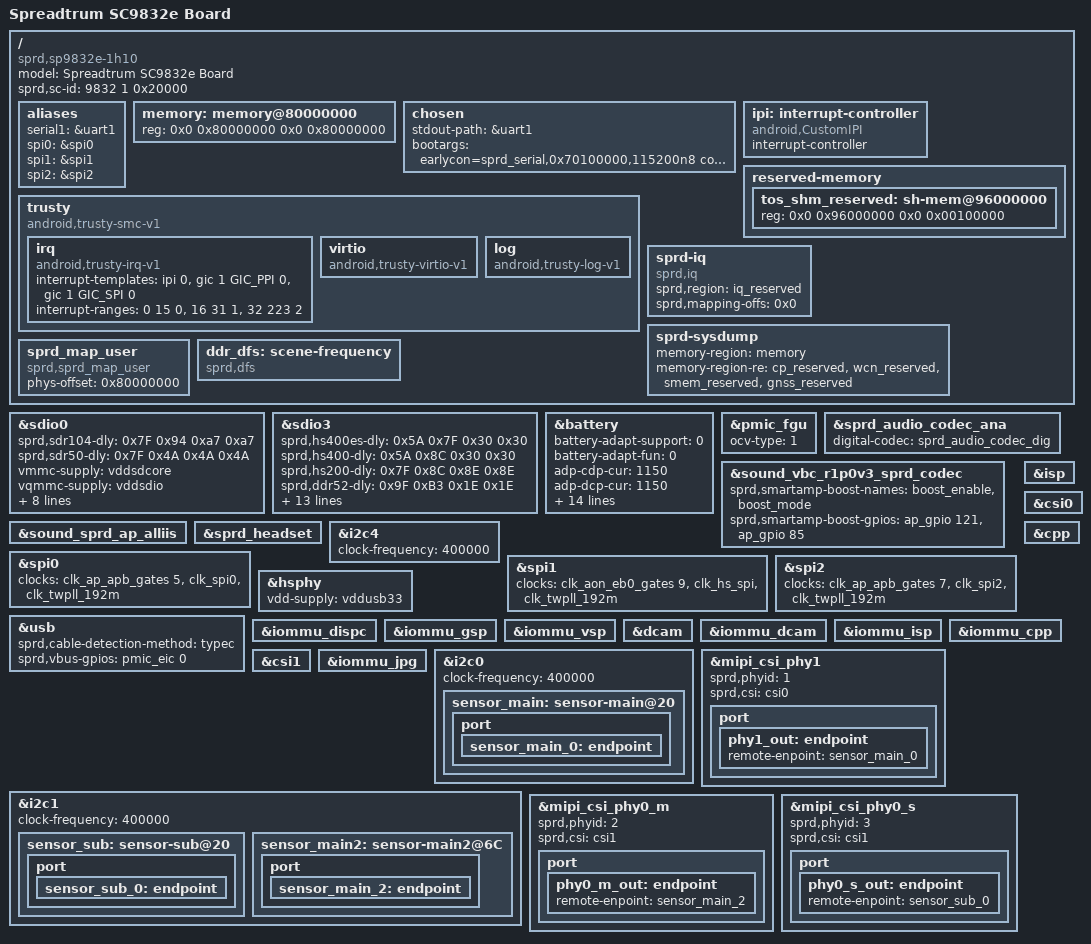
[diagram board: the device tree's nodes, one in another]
/*
 * Spreadtrum sharkle sp9832e board DTS file
 *
 * Copyright (C) 2017, Spreadtrum Communications Inc.
 *
 * This file is licensed under a dual GPLv2 or X11 license.
 */
/dts-v1/;

#include "sp9832e-common.dtsi"

/ {
	model = "Spreadtrum SC9832e Board";

	compatible = "sprd,sp9832e-1h10", "sprd,sc9832e";

	sprd,sc-id = <9832 1 0x20000>;

	aliases {
		serial1 = &uart1;
		spi0 = &spi0;
		spi1 = &spi1;
		spi2 = &spi2;
	};

	memory: memory@80000000 {
		device_type = "memory";
		reg = <0x0 0x80000000 0x0 0x80000000>;
	};

	chosen {
		stdout-path = &uart1;
		bootargs = "earlycon=sprd_serial,0x70100000,115200n8 console=ttyS1,115200n8 loglevel=1 init=/init root=/dev/mmcblk0p30 rootfstype=ext4 ro rootwait androidboot.hardware=sp9832e_1h10 androidboot.dtbo_idx=0";
	};

	ipi: interrupt-controller {
		compatible = "android,CustomIPI";
		#interrupt-cells = <1>;
		interrupt-controller;
	};

	/* reserved memory for spec board */
	reserved-memory {
		#address-cells = <2>;
		#size-cells = <2>;
		ranges;

		tos_shm_reserved: sh-mem@96000000{
			reg = <0x0 0x96000000 0x0 0x00100000>;
		};
	};

	trusty {
		compatible = "android,trusty-smc-v1";

		irq {
			compatible = "android,trusty-irq-v1";
			interrupt-templates = <&ipi 0>,
						<&gic 1 GIC_PPI 0>,
						<&gic 1 GIC_SPI 0>;
			interrupt-ranges = < 0  15 0>,
						<16  31 1>,
						<32 223 2>;
		};

		virtio {
			compatible = "android,trusty-virtio-v1";
		};

		log {
			compatible = "android,trusty-log-v1";
		};
	};

	sprd-iq {
		compatible = "sprd,iq";
		sprd,region = <&iq_reserved>;
		sprd,mapping-offs = <0x0>;
	};

	sprd-sysdump {
		memory-region = <&memory>;
		memory-region-re = <&cp_reserved>, <&wcn_reserved>,
				   <&smem_reserved>, <&gnss_reserved>;
	};

	sprd_map_user {
		compatible = "sprd,sprd_map_user";
		phys-offset = <0x80000000>;
	};

	ddr_dfs: scene-frequency {
		compatible = "sprd,dfs";
	};
};

&sdio0 {
	sprd,sdr104-dly = <0x7F 0x94 0xa7 0xa7>;
	sprd,sdr50-dly = <0x7F 0x4A 0x4A 0x4A>;
	vmmc-supply = <&vddsdcore>;
	vqmmc-supply = <&vddsdio>;
	voltage-ranges = <3000 3000>;
	bus-width = <4>;
	cd-gpios = <&ap_gpio 78 1>;
	sd-uhs-sdr50;
	sprd,name = "sdio_sd";
	sprd,sdio-adma;
	no-sdio;
	no-mmc;
	status = "okay";
};

&sdio3 {
	sprd,hs400es-dly = <0x5A 0x7F 0x30 0x30>;
	sprd,hs400-dly = <0x5A 0x8C 0x30 0x30>;
	sprd,hs200-dly = <0x7F 0x8C 0x8E 0x8E>;
	sprd,ddr52-dly = <0x9F 0xB3 0x1E 0x1E>;
	vmmc-supply = <&vddemmccore>;
	voltage-ranges = <3000 3000>;
	bus-width = <8>;
	non-removable;
	cap-mmc-hw-reset;
	mmc-hs400-enhanced-strobe;
	mmc-hs400-1_8v;
	mmc-hs200-1_8v;
	mmc-ddr-1_8v;
	sprd,name = "sdio_emmc";
	sprd,sdio-adma;
	no-sdio;
	no-sd;
	status = "okay";
};

&battery {
	battery-adapt-support = <0>;
	battery-adapt-fun = <0>;
	adp-cdp-cur = <1150>;
	adp-dcp-cur = <1150>;
	adp-sdp-cur = <550>;
	adp-unknown-cur = <550>;
	chg-end-vol = <4350>;
	chg-end-vol-check = <4330>;
	chg-bat-safety-vol = <4430>;
	rechg-vol = <4270>;
	rsense-real = <200>;
	rint = <320>;
	cnom = <2780>;
	chg-polling-time = <10>;
	ocv-tab-vol = <4360 4249 4189 4133 4081 4034 3991
			3953 3910 3866 3836 3813 3795 3782
			3774 3765 3750 3726 3687 3658 3400>;
	ocv-tab-cap = <100  95   90   85   80   75   70
			65   60   55   50   45   40   35
			30   25   20   15   10   5   0>;
};



&pmic_fgu {
	ocv-type = <1>;
};

&sprd_audio_codec_ana {
	status = "okay";
	digital-codec = <&sprd_audio_codec_dig>;
};

&sound_vbc_r1p0v3_sprd_codec {
	status = "okay";
	sprd,smartamp-boost-names = "boost_enable", "boost_mode";
	sprd,smartamp-boost-gpios = <&ap_gpio 121 0>,
			<&ap_gpio 85 0>;
};

&sound_sprd_ap_alliis {
	status = "okay";
};

&sprd_headset {
	status = "okay";
};

&i2c4 {
	status = "okay";
	clock-frequency = <400000>;
};

&spi0 {
	/*used for fingerprint sensor*/
	status = "okay";
	clocks = <&clk_ap_apb_gates 5>, <&clk_spi0>, <&clk_twpll_192m>;
};

&spi1 {
	clocks = <&clk_aon_eb0_gates 9>, <&clk_hs_spi>, <&clk_twpll_192m>;
};

&spi2 {
	clocks = <&clk_ap_apb_gates 7>, <&clk_spi2>, <&clk_twpll_192m>;
};

&hsphy {
	vdd-supply = <&vddusb33>;
};

&usb {
	sprd,cable-detection-method = "typec";
	sprd,vbus-gpios = <&pmic_eic 0 0>;
};

&iommu_dispc {
	status = "okay";
};

&iommu_gsp {
	status = "okay";
};

&iommu_vsp {
	status = "okay";
};

&dcam {
	status = "okay";
};

&iommu_dcam {
	status = "okay";
};

&isp {
	status = "okay";
};

&iommu_isp {
	status = "okay";
};

&csi0 {
	status = "okay";
};

&cpp {
	status = "okay";
};

&iommu_cpp {
	status = "okay";
};

&csi1 {
	status = "okay";
};

&iommu_jpg {
	 status = "okay";
};


&i2c0 {
	status = "okay";
	clock-frequency = <400000>;

	sensor_main: sensor-main@20 {
		port {
			sensor_main_0: endpoint {
			};
		};
	};
};

&i2c1 {
	status = "okay";
	clock-frequency = <400000>;

	sensor_sub: sensor-sub@20 {
		port {
			sensor_sub_0: endpoint {
			};
		};
	};

	sensor_main2: sensor-main2@6C {
		port {
			sensor_main_2: endpoint {
			};
		};
	};
};

&mipi_csi_phy1 {
	status = "okay";
	sprd,phyid = <1>;
	sprd,csi = <&csi0>;
	port {
	phy1_out: endpoint {
		remote-enpoint = <&sensor_main_0>;
		};
	};
};

&mipi_csi_phy0_m {
	status = "okay";
	sprd,phyid = <2>;
	sprd,csi = <&csi1>;
	port {
	phy0_m_out: endpoint {
		remote-enpoint = <&sensor_main_2>;
		};
	};
};

&mipi_csi_phy0_s {
	status = "okay";
	sprd,phyid = <3>;
	sprd,csi = <&csi1>;
	port {
	phy0_s_out: endpoint {
		remote-enpoint = <&sensor_sub_0>;
		};
	};
};
